# STM32H7R register map
File version: 1.3
CPU: CM7 r0p1, little endian, MPU, FPU, 4 interrupt priority bits
Registers are 32-bit, read-write, reset 0x0 unless marked. A register's access mark holds for its fields unless they carry their own. Offsets are from the block's base; [hi:lo] are bit positions; {n}, {i} and the like mark numbered series.

## SDMMC1 — Secure digital input/output MultiMediaCard interface
Base 0x52007000
Same registers: SDMMC2 0x48002400
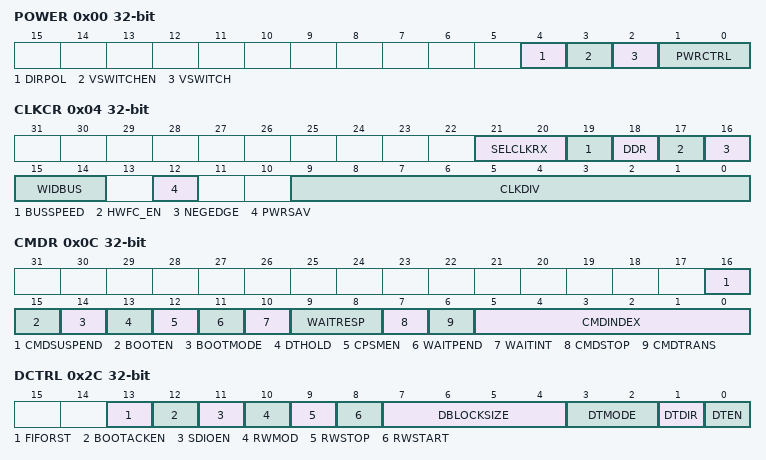
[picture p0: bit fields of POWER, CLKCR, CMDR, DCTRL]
0x00 POWER — SDMMC power control register
  [4] DIRPOL — Data and command direction signals polarity selection This bit can only be written when the SDMMC is in the power-off state (PWRCTRL = 00).
  [3] VSWITCHEN — Voltage switch procedure enable This bit can only be written by firmware when CPSM is disabled (CPSMEN = 0). This bit is used to stop the SDMMC_CK after the voltage switch command response:
  [2] VSWITCH — Voltage switch sequence start This bit is used to start the timing critical section of the voltage switch sequence:
  [1:0] PWRCTRL — SDMMC state control bits These bits can only be written when the SDMMC is not in the power-on state (PWRCTRL different from 11). These bits are used to define the functional state of the SDMMC signals: When written 00, power-off: the SDMMC is disabled and the clock to the card is stopped, SDMMC_D[7:0], SDMMC_CMD and SDMMC_CK are driven high. Any further write is ignored, PWRCTRL value keeps 11.
0x04 CLKCR — SDMMC clock control register
  [21:20] SELCLKRX — Receive clock selection These bits can only be written when the CPSM and DPSM are not active (CPSMACT = 0 and DPSMACT = 0)
  [19] BUSSPEED — Bus speed for selection of SDMMC operating modes This bit can only be written when the CPSM and DPSM are not active (CPSMACT = 0 and DPSMACT = 0)
  [18] DDR — Data rate signaling selection This bit can only be written when the CPSM and DPSM are not active (CPSMACT = 0 and DPSMACT = 0) DDR rate must only be selected with 4-bit or 8-bit wide bus mode. (WIDBUS > 00). DDR = 1 has no effect when WIDBUS = 00 (1-bit wide bus). DDR rate must only be selected with clock division >1. (CLKDIV > 0)
  [17] HWFC_EN — Hardware flow control enable This bit can only be written when the CPSM and DPSM are not active (CPSMACT = 0 and DPSMACT = 0) When Hardware flow control is enabled, the meaning of the TXFIFOE and RXFIFOF flags change, see SDMMC status register definition in Section 58.10.11.
  [16] NEGEDGE — SDMMC_CK dephasing selection bit for data and command This bit can only be written when the CPSM and DPSM are not active (CPSMACT = 0 and DPSMACT = 0). When clock division = 1 (CLKDIV = 0), this bit has no effect. Data and Command change on SDMMC_CK falling edge. Command and data changed on the sdmmc_ker_ck falling edge succeeding the rising edge of SDMMC_CK. SDMMC_CK edge occurs on sdmmc_ker_ck rising edge. When clock division >1 (CLKDIV > 0) & DDR = 1: Command changed on the sdmmc_ker_ck falling edge succeeding the rising edge of SDMMC_CK. Data changed on the sdmmc_ker_ck falling edge succeeding a SDMMC_CK edge. SDMMC_CK edge occurs on sdmmc_ker_ck rising edge. Command and data changed on the same sdmmc_ker_ck rising edge generating the SDMMC_CK falling edge. When clock division >1 (CLKDIV > 0) & DDR = 1: Command changed on the same sdmmc_ker_ck rising edge generating the SDMMC_CK falling edge. Data changed on the SDMMC_CK falling edge succeeding a SDMMC_CK edge. SDMMC_CK edge occurs on sdmmc_ker_ck rising edge.
  [15:14] WIDBUS — Wide bus mode enable bit This bit can only be written when the CPSM and DPSM are not active (CPSMACT = 0 and DPSMACT = 0)
  [12] PWRSAV — Power saving configuration bit This bit can only be written when the CPSM and DPSM are not active (CPSMACT = 0 and DPSMACT = 0) For power saving, the SDMMC_CK clock output can be disabled when the bus is idle by setting PWRSAV:
  [9:0] CLKDIV — Clock divide factor This bit can only be written when the CPSM and DPSM are not active (CPSMACT = 0 and DPSMACT = 0). This field defines the divide factor between the input clock (sdmmc_ker_ck) and the output clock (SDMMC_CK): SDMMC_CK frequency = sdmmc_ker_ck / [2 * CLKDIV]. 0x0XX: etc.. 0xXXX: etc..
0x08 ARGR — SDMMC argument register
  [31:0] CMDARG — Command argument These bits can only be written by firmware when CPSM is disabled (CPSMEN = 0). Command argument sent to a card as part of a command message. If a command contains an argument, it must be loaded into this register before writing a command to the command register.
0x0C CMDR — SDMMC command register
  [16] CMDSUSPEND — The CPSM treats the command as a Suspend or Resume command and signals interrupt period start/end This bit can only be written by firmware when CPSM is disabled (CPSMEN = 0). CMDSUSPEND = 1 and CMDTRANS = 0 Suspend command, start interrupt period when response bit BS=0. CMDSUSPEND = 1 and CMDTRANS = 1 Resume command with data, end interrupt period when response bit DF=1.
  [15] BOOTEN — Enable boot mode procedure
  [14] BOOTMODE — Select the boot mode procedure to be used This bit can only be written by firmware when CPSM is disabled (CPSMEN = 0)
  [13] DTHOLD — Hold new data block transmission and reception in the DPSM If this bit is set, the DPSM does not move from the Wait_S state to the Send state or from the Wait_R state to the Receive state.
  [12] CPSMEN — Command path state machine (CPSM) enable bit This bit is written 1 by firmware, and cleared by hardware when the CPSM enters the Idle state. If this bit is set, the CPSM is enabled. When DTEN = 1, no command is transfered nor boot procedure is started. CPSMEN is cleared to 0. During Read Wait with SDMMC_CK stopped no command is sent and CPSMEN is kept 0.
  [11] WAITPEND — CPSM waits for end of data transfer (CmdPend internal signal) from DPSM This bit when set, the CPSM waits for the end of data transfer trigger before it starts sending a command. WAITPEND is only taken into account when DTMODE = e.MMC stream data transfer, WIDBUS = 1-bit wide bus mode, DPSMACT = 1 and DTDIR = from host to card.
  [10] WAITINT — CPSM waits for interrupt request If this bit is set, the CPSM disables command timeout and waits for an card interrupt request (Response). If this bit is cleared in the CPSM Wait state, it causes the abort of the interrupt mode.
  [9:8] WAITRESP — Wait for response bits This bit can only be written by firmware when CPSM is disabled (CPSMEN = 0). They are used to configure whether the CPSM is to wait for a response, and if yes, which kind of response.
  [7] CMDSTOP — The CPSM treats the command as a Stop Transmission command and signals abort to the DPSM This bit can only be written by firmware when CPSM is disabled (CPSMEN = 0). If this bit is set, the CPSM issues the abort signal to the DPSM when the command is sent.
  [6] CMDTRANS — The CPSM treats the command as a data transfer command, stops the interrupt period, and signals DataEnable to the DPSM This bit can only be written by firmware when CPSM is disabled (CPSMEN = 0). If this bit is set, the CPSM issues an end of interrupt period and issues DataEnable signal to the DPSM when the command is sent.
  [5:0] CMDINDEX — Command index This bit can only be written by firmware when CPSM is disabled (CPSMEN = 0). The command index is sent to the card as part of a command message.
0x10 RESPCMDR ro — SDMMC command response register
  [5:0] RESPCMD — Response command index Read-only bit field. Contains the command index of the last command response received.
{0x10+4i} RESP{i}R ro (i=1..4) — SDMMC response {i} register
  [31:0] CARDSTATUS — Card status according table below See Table 444.
0x24 DTIMER — SDMMC data timer register
  [31:0] DATATIME — Data and R1b busy timeout period This bit can only be written when the CPSM and DPSM are not active (CPSMACT = 0 and DPSMACT = 0). Data and R1b busy timeout period expressed in card bus clock periods.
0x28 DLENR — SDMMC data length register
  [24:0] DATALENGTH — Data length value This register can only be written by firmware when DPSM is inactive (DPSMACT = 0). Number of data bytes to be transferred. When DDR = 1 DATALENGTH is truncated to a multiple of 2. (The last odd byte is not transfered) When DATALENGTH = 0 no data are transfered, when requested by a CPSMEN and CMDTRANS = 1 also no command is transfered. DTEN and CPSMEN are cleared to 0.
0x2C DCTRL — SDMMC data control register
  [13] FIFORST — FIFO reset, flushes any remaining data This bit can only be written by firmware when IDMAEN= 0 and DPSM is active (DPSMACT = 1). This bit only takes effect when a transfer error or transfer hold occurs.
  [12] BOOTACKEN — Enable the reception of the boot acknowledgment This bit can only be written by firmware when DPSM is inactive (DPSMACT = 0).
  [11] SDIOEN — SD I/O interrupt enable functions This bit can only be written by firmware when DPSM is inactive (DPSMACT = 0). If this bit is set, the DPSM enables the SD I/O card specific interrupt operation.
  [10] RWMOD — Read Wait mode This bit can only be written by firmware when DPSM is inactive (DPSMACT = 0).
  [9] RWSTOP — Read Wait stop This bit is written by firmware and auto cleared by hardware when the DPSM moves from the R_W state to the Wait_R or Idle state.
  [8] RWSTART — Read Wait start If this bit is set, Read Wait operation starts.
  [7:4] DBLOCKSIZE — Data block size This bit can only be written by firmware when DPSM is inactive (DPSMACT = 0). Define the data block length when the block data transfer mode is selected: When DATALENGTH is not a multiple of DBLOCKSIZE, the transfered data is truncated at a multiple of DBLOCKSIZE. (None of the remaining data are transfered.) When DDR = 1, DBLOCKSIZE = 0000 must not be used. (No data are transfered)
  [3:2] DTMODE — Data transfer mode selection This bit can only be written by firmware when DPSM is inactive (DPSMACT = 0).
  [1] DTDIR — Data transfer direction selection This bit can only be written by firmware when DPSM is inactive (DPSMACT = 0).
  [0] DTEN — Data transfer enable bit This bit can only be written by firmware when DPSM is inactive (DPSMACT = 0). This bit is cleared by Hardware when data transfer completes. This bit must only be used to transfer data when no associated data transfer command is used, i.e. must not be used with SD or e.MMC cards.
0x30 DCNTR ro — SDMMC data counter register
  [24:0] DATACOUNT — Data count value When read, the number of remaining data bytes to be transferred is returned. Write has no effect.
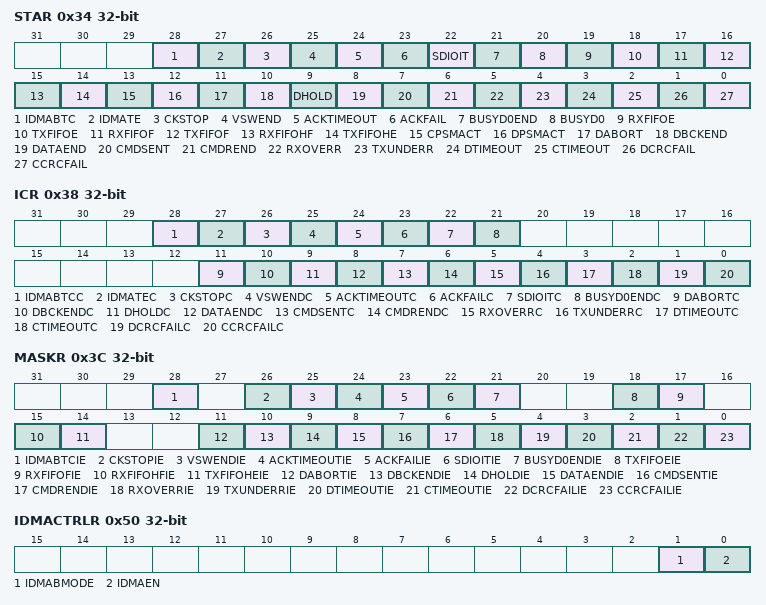
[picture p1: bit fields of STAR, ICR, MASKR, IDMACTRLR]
0x34 STAR ro — SDMMC status register
  [28] IDMABTC — IDMA buffer transfer complete The interrupt flag is cleared by writing corresponding interrupt clear bit in SDMMC_ICR.
  [27] IDMATE — IDMA transfer error The interrupt flag is cleared by writing corresponding interrupt clear bit in SDMMC_ICR.
  [26] CKSTOP — SDMMC_CK stopped in Voltage switch procedure The interrupt flag is cleared by writing corresponding interrupt clear bit in SDMMC_ICR.
  [25] VSWEND — Voltage switch critical timing section completion The interrupt flag is cleared by writing corresponding interrupt clear bit in SDMMC_ICR.
  [24] ACKTIMEOUT — Boot acknowledgment timeout The interrupt flag is cleared by writing corresponding interrupt clear bit in SDMMC_ICR.
  [23] ACKFAIL — Boot acknowledgment received (boot acknowledgment check fail) The interrupt flag is cleared by writing corresponding interrupt clear bit in SDMMC_ICR.
  [22] SDIOIT — SDIO interrupt received The interrupt flag is cleared by writing corresponding interrupt clear bit in SDMMC_ICR.
  [21] BUSYD0END — end of SDMMC_D0 Busy following a CMD response detected This indicates only end of busy following a CMD response. This bit does not signal busy due to data transfer. Interrupt flag is cleared by writing corresponding interrupt clear bit in SDMMC_ICR.
  [20] BUSYD0 — Inverted value of SDMMC_D0 line (Busy), sampled at the end of a CMD response and a second time 2 SDMMC_CK cycles after the CMD response This bit is reset to not busy when the SDMMCD0 line changes from busy to not busy. This bit does not signal busy due to data transfer. This is a hardware status flag only, it does not generate an interrupt.
  [19] RXFIFOE — Receive FIFO empty This is a hardware status flag only, does not generate an interrupt. This bit is cleared when one FIFO location becomes full.
  [18] TXFIFOE — Transmit FIFO empty This bit is cleared when one FIFO location becomes full.
  [17] RXFIFOF — Receive FIFO full This bit is cleared when one FIFO location becomes empty.
  [16] TXFIFOF — Transmit FIFO full This is a hardware status flag only, does not generate an interrupt. This bit is cleared when one FIFO location becomes empty.
  [15] RXFIFOHF — Receive FIFO half full There are at least half the number of words in the FIFO. This bit is cleared when the FIFO becomes half+1 empty.
  [14] TXFIFOHE — Transmit FIFO half empty At least half the number of words can be written into the FIFO. This bit is cleared when the FIFO becomes half+1 full.
  [13] CPSMACT — Command path state machine active, i.e. not in Idle state This is a hardware status flag only, does not generate an interrupt.
  [12] DPSMACT — Data path state machine active, i.e. not in Idle state This is a hardware status flag only, does not generate an interrupt.
  [11] DABORT — Data transfer aborted by CMD12 Interrupt flag is cleared by writing corresponding interrupt clear bit in SDMMC_ICR.
  [10] DBCKEND — Data block sent/received DBCKEND is set when: - CRC check passed and DPSM moves to the R_W state or - IDMAEN = 0 and transmit data transfer hold and DATACOUNT >0 and DPSM moves to Wait_S. Interrupt flag is cleared by writing corresponding interrupt clear bit in SDMMC_ICR.
  [9] DHOLD — Data transfer Hold Interrupt flag is cleared by writing corresponding interrupt clear bit in SDMMC_ICR.
  [8] DATAEND — Data transfer ended correctly DATAEND is set if data counter DATACOUNT is zero and no errors occur, and no transmit data transfer hold. Interrupt flag is cleared by writing corresponding interrupt clear bit in SDMMC_ICR.
  [7] CMDSENT — Command sent (no response required) Interrupt flag is cleared by writing corresponding interrupt clear bit in SDMMC_ICR.
  [6] CMDREND — Command response received (CRC check passed, or no CRC) Interrupt flag is cleared by writing corresponding interrupt clear bit in SDMMC_ICR.
  [5] RXOVERR — Received FIFO overrun error (masked by hardware when IDMA is enabled) Interrupt flag is cleared by writing corresponding interrupt clear bit in SDMMC_ICR.
  [4] TXUNDERR — Transmit FIFO underrun error (masked by hardware when IDMA is enabled) Interrupt flag is cleared by writing corresponding interrupt clear bit in SDMMC_ICR.
  [3] DTIMEOUT — Data timeout Interrupt flag is cleared by writing corresponding interrupt clear bit in SDMMC_ICR.
  [2] CTIMEOUT — Command response timeout Interrupt flag is cleared by writing corresponding interrupt clear bit in SDMMC_ICR. The Command Timeout period has a fixed value of 64 SDMMC_CK clock periods.
  [1] DCRCFAIL — Data block sent/received (CRC check failed) Interrupt flag is cleared by writing corresponding interrupt clear bit in SDMMC_ICR.
  [0] CCRCFAIL — Command response received (CRC check failed) Interrupt flag is cleared by writing corresponding interrupt clear bit in SDMMC_ICR.
0x38 ICR — SDMMC interrupt clear register
  [28] IDMABTCC — IDMA buffer transfer complete clear bit Set by software to clear the IDMABTC flag.
  [27] IDMATEC — IDMA transfer error clear bit Set by software to clear the IDMATE flag.
  [26] CKSTOPC — CKSTOP flag clear bit Set by software to clear the CKSTOP flag.
  [25] VSWENDC — VSWEND flag clear bit Set by software to clear the VSWEND flag.
  [24] ACKTIMEOUTC — ACKTIMEOUT flag clear bit Set by software to clear the ACKTIMEOUT flag.
  [23] ACKFAILC — ACKFAIL flag clear bit Set by software to clear the ACKFAIL flag.
  [22] SDIOITC — SDIOIT flag clear bit Set by software to clear the SDIOIT flag.
  [21] BUSYD0ENDC — BUSYD0END flag clear bit Set by software to clear the BUSYD0END flag.
  [11] DABORTC — DABORT flag clear bit Set by software to clear the DABORT flag.
  [10] DBCKENDC — DBCKEND flag clear bit Set by software to clear the DBCKEND flag.
  [9] DHOLDC — DHOLD flag clear bit Set by software to clear the DHOLD flag.
  [8] DATAENDC — DATAEND flag clear bit Set by software to clear the DATAEND flag.
  [7] CMDSENTC — CMDSENT flag clear bit Set by software to clear the CMDSENT flag.
  [6] CMDRENDC — CMDREND flag clear bit Set by software to clear the CMDREND flag.
  [5] RXOVERRC — RXOVERR flag clear bit Set by software to clear the RXOVERR flag.
  [4] TXUNDERRC — TXUNDERR flag clear bit Set by software to clear TXUNDERR flag.
  [3] DTIMEOUTC — DTIMEOUT flag clear bit Set by software to clear the DTIMEOUT flag.
  [2] CTIMEOUTC — CTIMEOUT flag clear bit Set by software to clear the CTIMEOUT flag.
  [1] DCRCFAILC — DCRCFAIL flag clear bit Set by software to clear the DCRCFAIL flag.
  [0] CCRCFAILC — CCRCFAIL flag clear bit Set by software to clear the CCRCFAIL flag.
0x3C MASKR — SDMMC mask register
  [28] IDMABTCIE — IDMA buffer transfer complete interrupt enable Set and cleared by software to enable/disable the interrupt generated when the IDMA has transferred all data belonging to a memory buffer.
  [26] CKSTOPIE — Voltage Switch clock stopped interrupt enable Set and cleared by software to enable/disable interrupt caused by Voltage Switch clock stopped.
  [25] VSWENDIE — Voltage switch critical timing section completion interrupt enable Set and cleared by software to enable/disable the interrupt generated when voltage switch critical timing section completion.
  [24] ACKTIMEOUTIE — Acknowledgment timeout interrupt enable Set and cleared by software to enable/disable interrupt caused by acknowledgment timeout.
  [23] ACKFAILIE — Acknowledgment Fail interrupt enable Set and cleared by software to enable/disable interrupt caused by acknowledgment Fail.
  [22] SDIOITIE — SDIO mode interrupt received interrupt enable Set and cleared by software to enable/disable the interrupt generated when receiving the SDIO mode interrupt.
  [21] BUSYD0ENDIE — BUSYD0END interrupt enable Set and cleared by software to enable/disable the interrupt generated when SDMMC_D0 signal changes from busy to NOT busy following a CMD response.
  [18] TXFIFOEIE — Tx FIFO empty interrupt enable Set and cleared by software to enable/disable interrupt caused by Tx FIFO empty.
  [17] RXFIFOFIE — Rx FIFO full interrupt enable Set and cleared by software to enable/disable interrupt caused by Rx FIFO full.
  [15] RXFIFOHFIE — Rx FIFO half full interrupt enable Set and cleared by software to enable/disable interrupt caused by Rx FIFO half full.
  [14] TXFIFOHEIE — Tx FIFO half empty interrupt enable Set and cleared by software to enable/disable interrupt caused by Tx FIFO half empty.
  [11] DABORTIE — Data transfer aborted interrupt enable Set and cleared by software to enable/disable interrupt caused by a data transfer being aborted.
  [10] DBCKENDIE — Data block end interrupt enable Set and cleared by software to enable/disable interrupt caused by data block end.
  [9] DHOLDIE — Data hold interrupt enable Set and cleared by software to enable/disable the interrupt generated when sending new data is hold in the DPSM Wait_S state.
  [8] DATAENDIE — Data end interrupt enable Set and cleared by software to enable/disable interrupt caused by data end.
  [7] CMDSENTIE — Command sent interrupt enable Set and cleared by software to enable/disable interrupt caused by sending command.
  [6] CMDRENDIE — Command response received interrupt enable Set and cleared by software to enable/disable interrupt caused by receiving command response.
  [5] RXOVERRIE — Rx FIFO overrun error interrupt enable Set and cleared by software to enable/disable interrupt caused by Rx FIFO overrun error.
  [4] TXUNDERRIE — Tx FIFO underrun error interrupt enable Set and cleared by software to enable/disable interrupt caused by Tx FIFO underrun error.
  [3] DTIMEOUTIE — Data timeout interrupt enable Set and cleared by software to enable/disable interrupt caused by data timeout.
  [2] CTIMEOUTIE — Command timeout interrupt enable Set and cleared by software to enable/disable interrupt caused by command timeout.
  [1] DCRCFAILIE — Data CRC fail interrupt enable Set and cleared by software to enable/disable interrupt caused by data CRC failure.
  [0] CCRCFAILIE — Command CRC fail interrupt enable Set and cleared by software to enable/disable interrupt caused by command CRC failure.
0x40 ACKTIMER — SDMMC acknowledgment timer register
  [24:0] ACKTIME — Boot acknowledgment timeout period This bit can only be written by firmware when CPSM is disabled (CPSMEN = 0). Boot acknowledgment timeout period expressed in card bus clock periods.
0x50 IDMACTRLR — SDMMC DMA control register
  [1] IDMABMODE — Buffer mode selection This bit can only be written by firmware when DPSM is inactive (DPSMACT = 0).
  [0] IDMAEN — IDMA enable This bit can only be written by firmware when DPSM is inactive (DPSMACT = 0).
0x54 IDMABSIZER — SDMMC IDMA buffer size register
  [16:5] IDMABNDT — Number of bytes per buffer This 12-bit value must be multiplied by 8 to get the size of the buffer in 32-bit words and by 32 to get the size of the buffer in bytes. Example: IDMABNDT = 0x001: buffer size = 8 words = 32 bytes. Example: IDMABNDT = 0x800: buffer size = 16384 words = 64 Kbyte. These bits can only be written by firmware when DPSM is inactive (DPSMACT = 0).
0x58 IDMABASER — SDMMC IDMA buffer base address register
  [31:0] IDMABASE — Buffer memory base address bits [31:2], must be word aligned (bit [1:0] are always 0 and read only) This register can be written by firmware when DPSM is inactive (DPSMACT = 0), and can dynamically be written by firmware when DPSM active (DPSMACT = 1).
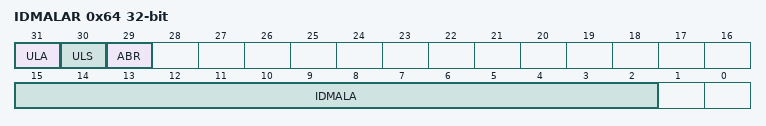
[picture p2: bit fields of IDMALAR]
0x64 IDMALAR — SDMMC IDMA linked list address register
  [31] ULA — Update SDMMC_IDMALAR from linked list when in linked list mode (SDMMC_IDMACTRLR.IDMABMODE select linked list mode) This bit can only be written by firmware when DPSM is inactive (DPSMACT = 0).
  [30] ULS — Update SDMMC_IDMABSIZE from the next linked list when in linked list mode (SDMMC_IDMACTRLR.IDMABMODE select linked list mode and ULA = 1) This bit can only be written by firmware when DPSM is inactive (DPSMACT = 0).
  [29] ABR — Acknowledge linked list buffer ready This bit can only be written by firmware when DPSM is inactive (DPSMACT = 0). This bit is not taken into account when starting the first linked list buffer from the software programmed register information. ABR is only taken into account on subsequent loaded linked list items.
  [15:2] IDMALA — Word aligned linked list item address offset Linked list item offset pointer to the base of the next linked list item structure. Linked list item base address is IDMABA + IDMALA. These bits can only be written by firmware when DPSM is inactive (DPSMACT = 0).
0x68 IDMABAR — SDMMC IDMA linked list memory base register
  [31:2] IDMABA — Word aligned Linked list memory base address Linked list memory base pointer. These bits can only be written by firmware when DPSM is inactive (DPSMACT = 0).
{0x80+4i} FIFOR{i} (i=0..15) — SDMMC data FIFO registers {i}
  [31:0] FIFODATA — Receive and transmit FIFO data This register can only be read or written by firmware when the DPSM is active (DPSMACT = 1). The FIFO data occupies 16 entries of 32-bit words.
